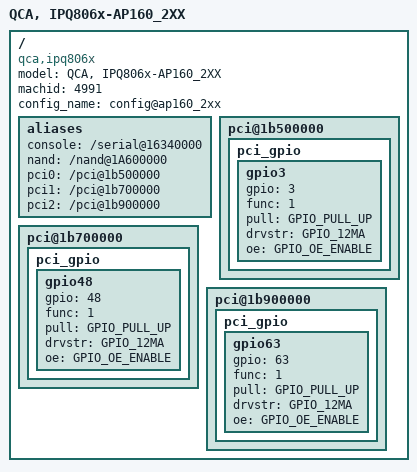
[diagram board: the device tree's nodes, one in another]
/*
 * Copyright (c) 2016, The Linux Foundation. All rights reserved.
 *
 * This program is free software; you can redistribute it and/or modify
 * it under the terms of the GNU General Public License version 2 and
 * only version 2 as published by the Free Software Foundation.
 *
 * This program is distributed in the hope that it will be useful,
 * but WITHOUT ANY WARRANTY; without even the implied warranty of
 * MERCHANTABILITY or FITNESS FOR A PARTICULAR PURPOSE.  See the
 * GNU General Public License for more details.
 */

/dts-v1/;
#include "ipq806x-soc.dtsi"
/ {
	model ="QCA, IPQ806x-AP160_2XX";
	compatible = "qca,ipq806x", "qca,ipq806x-ap160_2XX";
	machid = <4991>;
	config_name = "config@ap160_2xx";

	aliases {
		console = "/serial@16340000";
		nand = "/nand@1A600000";
		pci0 = "/pci@1b500000";
		pci1 = "/pci@1b700000";
		pci2 = "/pci@1b900000";
	};

	pci@1b500000 {
		pci_gpio {
			gpio3 {
				gpio = <3>;
				func = <1>;
				pull = <GPIO_PULL_UP>;
				drvstr = <GPIO_12MA>;
				oe = <GPIO_OE_ENABLE>;
			};
		};
	};

	pci@1b700000 {
		pci_gpio {
			gpio48 {
				gpio = <48>;
				func = <1>;
				pull = <GPIO_PULL_UP>;
				drvstr = <GPIO_12MA>;
				oe = <GPIO_OE_ENABLE>;
			};
		};
	};

	pci@1b900000 {
		pci_gpio {
			gpio63 {
				gpio = <63>;
				func = <1>;
				pull = <GPIO_PULL_UP>;
				drvstr = <GPIO_12MA>;
				oe = <GPIO_OE_ENABLE>;
			};
		};
	};

};
